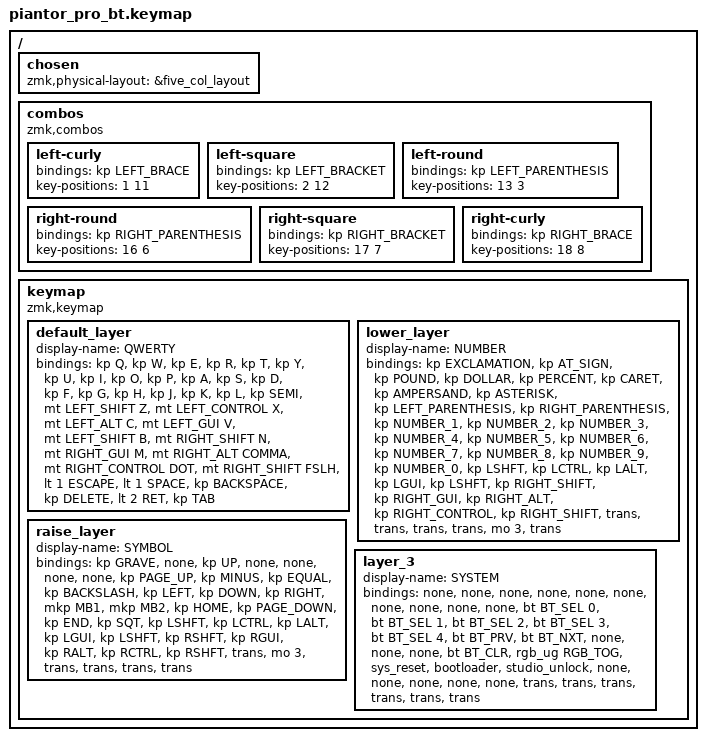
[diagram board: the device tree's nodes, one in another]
/*
 * Copyright (c) 2020 The ZMK Contributors
 *
 * SPDX-License-Identifier: MIT
 */

#include <behaviors.dtsi>
#include <dt-bindings/zmk/bt.h>
#include <dt-bindings/zmk/keys.h>
#include <dt-bindings/zmk/pointing.h>
#include <dt-bindings/zmk/rgb.h>

/ {
    chosen { zmk,physical-layout = &five_col_layout; };
};

/ {
    combos {
        compatible = "zmk,combos";

        left-curly {
            bindings = <&kp LEFT_BRACE>;
            key-positions = <1 11>;
        };

        left-square {
            bindings = <&kp LEFT_BRACKET>;
            key-positions = <2 12>;
        };

        left-round {
            bindings = <&kp LEFT_PARENTHESIS>;
            key-positions = <13 3>;
        };

        right-round {
            bindings = <&kp RIGHT_PARENTHESIS>;
            key-positions = <16 6>;
        };

        right-square {
            bindings = <&kp RIGHT_BRACKET>;
            key-positions = <17 7>;
        };

        right-curly {
            bindings = <&kp RIGHT_BRACE>;
            key-positions = <18 8>;
        };
    };

    keymap {
        compatible = "zmk,keymap";

        default_layer {
            display-name = "QWERTY";

            // --------------------------------------------------------------
            // |  Q  |  W  |  E  |  R  |  T  |  Y  |  U   |  I  |  O  |  P  |
            // |  A  |  S  |  D  |  F  |  G  |  H  |  J   |  K  |  L  |  ;  |
            // |  Z  |  X  |  C  |  V  |  B  |  N  |  M   |  ,  |  .  |  /  |
            //                    | GUI | LWR | SPC | ENT | RSE  | ALT |

            bindings = <
  &kp Q  &kp W  &kp E  &kp R  &kp T  &kp Y  &kp U  &kp I  &kp O  &kp P      &kp A  &kp S  &kp D  &kp F  &kp G  &kp H  &kp J  &kp K  &kp L  &kp SEMI      &mt LEFT_SHIFT Z  &mt LEFT_CONTROL X  &mt LEFT_ALT C  &mt LEFT_GUI V  &mt LEFT_SHIFT B  &mt RIGHT_SHIFT N  &mt RIGHT_GUI M  &mt RIGHT_ALT COMMA  &mt RIGHT_CONTROL DOT  &mt RIGHT_SHIFT FSLH    &lt 1 ESCAPE  &lt 1 SPACE  &kp BACKSPACE  &kp DELETE  &lt 2 RET  &kp TAB
            >;
        };

        lower_layer {
            display-name = "NUMBER";

            // ---------------------------------------------------------------
            // |  1  |  2  |  3  |  4  |  5    |  6  |  7  |  8  |  9  |  0  |
            // | BT1 | BT2 | BT3 | BT4 | BT5   | LFT | DWN |  UP | RGT |     |
            // | BTCR| RGB | RST | BOOT| Unlock|     |     |     |     |     |
            //                    | GUI |     | SPC   | ENT |     | ALT |

            bindings = <
  &kp EXCLAMATION  &kp AT_SIGN  &kp POUND  &kp DOLLAR  &kp PERCENT  &kp CARET  &kp AMPERSAND  &kp ASTERISK  &kp LEFT_PARENTHESIS  &kp RIGHT_PARENTHESIS      &kp NUMBER_1  &kp NUMBER_2  &kp NUMBER_3  &kp NUMBER_4  &kp NUMBER_5  &kp NUMBER_6  &kp NUMBER_7  &kp NUMBER_8  &kp NUMBER_9  &kp NUMBER_0      &kp LSHFT  &kp LCTRL  &kp LALT  &kp LGUI  &kp LSHFT  &kp RIGHT_SHIFT  &kp RIGHT_GUI  &kp RIGHT_ALT  &kp RIGHT_CONTROL  &kp RIGHT_SHIFT    &trans  &trans  &trans  &trans  &mo 3  &trans
            >;
        };

        raise_layer {
            display-name = "SYMBOL";

            // -------------------------------------------------------------
            // |  !  |  @  |  #  |  $  |  %  |  ^  |  &  |  *  |  (  |  )  |
            // |     |     |     |     |     |  -  |  =  |  [  |  ]  |  \  |
            // |     |     |     |     |     |  _  |  +  |  {  |  }  | "|" |
            //                    | GUI |     | SPC | ENT |     | ALT |

            bindings = <
  &kp GRAVE  &none  &kp UP  &none  &none  &none  &none  &kp PAGE_UP  &kp MINUS  &kp EQUAL      &kp BACKSLASH  &kp LEFT  &kp DOWN  &kp RIGHT  &mkp MB1  &mkp MB2  &kp HOME  &kp PAGE_DOWN  &kp END  &kp SQT      &kp LSHFT  &kp LCTRL  &kp LALT  &kp LGUI  &kp LSHFT  &kp RSHFT  &kp RGUI  &kp RALT  &kp RCTRL  &kp RSHFT    &trans  &mo 3  &trans  &trans  &trans  &trans
            >;
        };

        layer_3 {
            display-name = "SYSTEM";
            bindings = <
  &none  &none  &none  &none  &none  &none  &none  &none  &none  &none      &bt BT_SEL 0  &bt BT_SEL 1  &bt BT_SEL 2  &bt BT_SEL 3  &bt BT_SEL 4  &bt BT_PRV  &bt BT_NXT  &none  &none  &none      &bt BT_CLR  &rgb_ug RGB_TOG  &sys_reset  &bootloader  &studio_unlock  &none  &none  &none  &none  &none    &trans  &trans  &trans  &trans  &trans  &trans
            >;
        };
    };
};
